VERSION "1.1"

NS_ :

BS_ :

BU_ : EngineECU Cluster Gateway

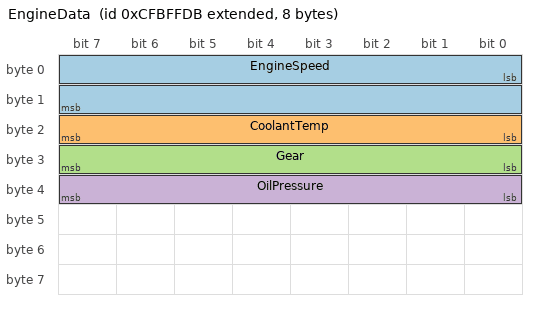
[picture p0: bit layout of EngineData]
BO_ 2365325275 EngineData: 8 EngineECU
 SG_ EngineSpeed : 0|16@1+ (0.25,0) [0|16063.75] "rpm" Cluster
 SG_ CoolantTemp : 16|8@1+ (1,-40) [-40|215] "degC" Cluster
 SG_ Gear : 24|8@1+ (1,0) [0|255] "" Cluster
 SG_ OilPressure : 32|8@1+ (2,0) [0|510] "kPa" Cluster

BO_ 500 VehicleState: 8 Cluster
 SG_ VehicleSpeed : 0|16@1+ (0.01,0) [0|655.35] "km/h" EngineECU
 SG_ Ignition : 16|1@1+ (1,0) [0|1] "" EngineECU

BO_ 600 GatewayStatus: 8 Gateway
 SG_ AliveCounter : 0|4@1+ (1,0) [0|15] "" Cluster

CM_ BO_ 217841627 "Powertrain measurements";
CM_ SG_ 217841627 EngineSpeed "Current engine speed with revised scaling";
VAL_ 217841627 Gear 0 "Neutral" 1 "First" 2 "Second" 3 "Third" ;
VAL_ 500 Ignition 0 "Off" 1 "On" ;
